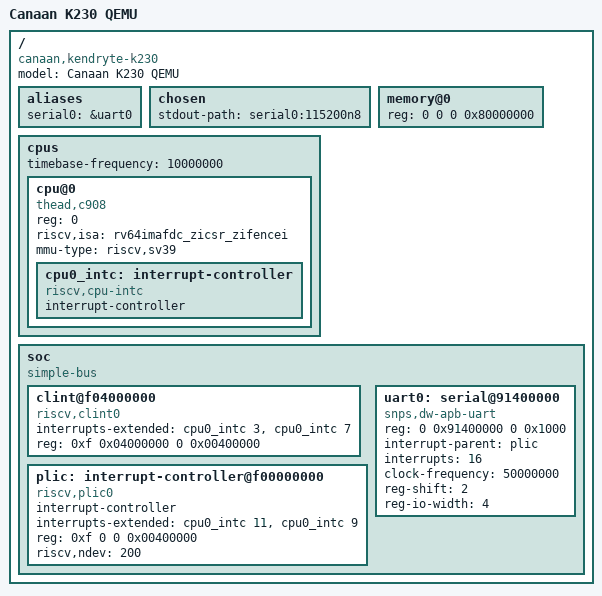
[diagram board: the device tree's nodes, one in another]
/dts-v1/;

/ {
	#address-cells = <2>;
	#size-cells = <2>;
	model = "Canaan K230 QEMU";
	compatible = "canaan,kendryte-k230";

	aliases {
		serial0 = &uart0;
	};

	chosen {
		stdout-path = "serial0:115200n8";
	};

	memory@0 {
		device_type = "memory";
		reg = <0 0 0 0x80000000>;
	};

	cpus {
		#address-cells = <1>;
		#size-cells = <0>;
		timebase-frequency = <10000000>;

		cpu@0 {
			device_type = "cpu";
			reg = <0>;
			compatible = "thead,c908", "riscv";
			riscv,isa = "rv64imafdc_zicsr_zifencei";
			mmu-type = "riscv,sv39";

			cpu0_intc: interrupt-controller {
				#interrupt-cells = <1>;
				compatible = "riscv,cpu-intc";
				interrupt-controller;
			};
		};
	};

	soc {
		#address-cells = <2>;
		#size-cells = <2>;
		compatible = "simple-bus";
		ranges;

		clint@f04000000 {
			compatible = "riscv,clint0";
			interrupts-extended = <&cpu0_intc 3 &cpu0_intc 7>;
			reg = <0xf 0x04000000 0 0x00400000>;
		};

		plic: interrupt-controller@f00000000 {
			#interrupt-cells = <1>;
			compatible = "riscv,plic0";
			interrupt-controller;
			interrupts-extended = <&cpu0_intc 11 &cpu0_intc 9>;
			reg = <0xf 0 0 0x00400000>;
			riscv,ndev = <200>;
		};

		uart0: serial@91400000 {
			compatible = "snps,dw-apb-uart";
			reg = <0 0x91400000 0 0x1000>;
			interrupt-parent = <&plic>;
			interrupts = <16>;
			clock-frequency = <50000000>;
			reg-shift = <2>;
			reg-io-width = <4>;
		};
	};
};
